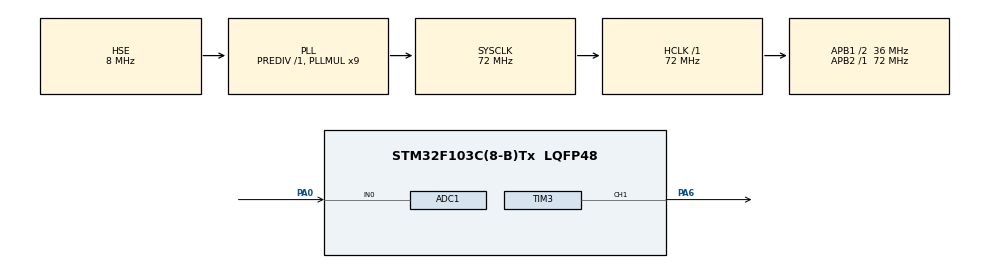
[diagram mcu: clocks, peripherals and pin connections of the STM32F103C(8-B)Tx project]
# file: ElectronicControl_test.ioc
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ADC1.Channel-0\#ChannelRegularConversion=ADC_CHANNEL_0
ADC1.ContinuousConvMode=ENABLE
ADC1.NbrOfConversionFlag=1
ADC1.Rank-0\#ChannelRegularConversion=1
ADC1.SamplingTime-0\#ChannelRegularConversion=ADC_SAMPLETIME_55CYCLES_5
ADC1.master=1
Dma.ADC1.0.Direction=DMA_PERIPH_TO_MEMORY
Dma.ADC1.0.Instance=DMA1_Channel1
Dma.ADC1.0.MemDataAlignment=DMA_MDATAALIGN_HALFWORD
Dma.ADC1.0.MemInc=DMA_MINC_ENABLE
Dma.ADC1.0.Mode=DMA_CIRCULAR
Dma.ADC1.0.PeriphDataAlignment=DMA_PDATAALIGN_HALFWORD
Dma.ADC1.0.PeriphInc=DMA_PINC_DISABLE
Dma.ADC1.0.Priority=DMA_PRIORITY_HIGH
Dma.Request0=ADC1
Mcu.Family=STM32F1
Mcu.Name=STM32F103C(8-B)Tx
Mcu.Package=LQFP48
NVIC.DMA1_Channel1_IRQn=true\:0\:0\:false\:false\:true\:false\:true\:true
NVIC.PriorityGroup=NVIC_PRIORITYGROUP_4
PA0-WKUP.Signal=ADCx_IN0
PA13.Mode=Serial_Wire
PA13.Signal=SYS_JTMS-SWDIO
PA14.Mode=Serial_Wire
PA14.Signal=SYS_JTCK-SWCLK
PA6.GPIO_Speed=GPIO_SPEED_FREQ_HIGH
PA6.Signal=S_TIM3_CH1
PD0-OSC_IN.Mode=HSE-External-Oscillator
PD0-OSC_IN.Signal=RCC_OSC_IN
PD1-OSC_OUT.Mode=HSE-External-Oscillator
PD1-OSC_OUT.Signal=RCC_OSC_OUT
ProjectManager.HeapSize=0x200
ProjectManager.StackSize=0x400
ProjectManager.TargetToolchain=CMake
RCC.ADCPresc=RCC_ADCPCLK2_DIV6
RCC.AHBFreq_Value=72000000
RCC.APB1CLKDivider=RCC_HCLK_DIV2
RCC.APB1Freq_Value=36000000
RCC.APB1TimFreq_Value=72000000
RCC.APB2Freq_Value=72000000
RCC.APB2TimFreq_Value=72000000
RCC.HCLKFreq_Value=72000000
RCC.PLLMUL=RCC_PLL_MUL9
RCC.PLLSourceVirtual=RCC_PLLSOURCE_HSE
RCC.SYSCLKFreq_VALUE=72000000
RCC.SYSCLKSource=RCC_SYSCLKSOURCE_PLLCLK
RCC.USBFreq_Value=72000000
SH.ADCx_IN0.0=ADC1_IN0,IN0
SH.S_TIM3_CH1.0=TIM3_CH1,PWM Generation1 CH1
TIM3.Channel-PWM\ Generation1\ CH1=TIM_CHANNEL_1
TIM3.Period=999
TIM3.Prescaler=71
board=custom

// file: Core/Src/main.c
/* USER CODE BEGIN Header */
/**
 ******************************************************************************
 * @file           : main.c
 * @brief          : Main program body
 ******************************************************************************
 * @attention
 *
 * Copyright (c) 2026 STMicroelectronics.
 * All rights reserved.
 *
 * This software is licensed under terms that can be found in the LICENSE file
 * in the root directory of this software component.
 * If no LICENSE file comes with this software, it is provided AS-IS.
 *
 ******************************************************************************
 */
/* USER CODE END Header */
#include "main.h"
#include "adc.h"
#include "dma.h"
#include "tim.h"
#include "gpio.h"

#include <stdint.h>

/* USER CODE BEGIN PV */
#define ADC_FULL_SCALE 4096U /* 12 位 ADC 满量程 */
#define MOVING_AVG_LEN 8U    /* 移动平均窗口长度 */

static uint16_t s_adc_raw = 0U;                     /* DMA 目标缓冲区 */
static uint16_t s_adc_filter[MOVING_AVG_LEN] = {0}; /* 滤波环形缓冲 */
static uint8_t s_adc_index = 0U;
static uint32_t s_adc_sum = 0U;
static uint32_t s_pwm_period = 0U; /* = ARR + 1，运行期读取 */
/* USER CODE END PV */

void SystemClock_Config(void);

int main(void) {

    /* MCU Configuration--------------------------------------------------------*/

    /* Reset of all peripherals, Initializes the Flash interface and the Systick. */
    HAL_Init();

    /* Configure the system clock */
    SystemClock_Config();

    /* Initialize all configured peripherals */
    MX_GPIO_Init();
    MX_DMA_Init();
    MX_ADC1_Init();
    MX_TIM3_Init();
    /* USER CODE BEGIN 2 */

    __HAL_TIM_SET_COMPARE(&htim3, TIM_CHANNEL_1, 0U); /* 上电先灭，避免满亮 */
    if (HAL_TIM_PWM_Start(&htim3, TIM_CHANNEL_1) != HAL_OK) {
        Error_Handler();
    }

    s_pwm_period = htim3.Init.Period + 1U; /* ARR=999 → 1000 */

    if (HAL_ADC_Start_DMA(&hadc1, (uint32_t *)&s_adc_raw, 1U) != HAL_OK) {
        Error_Handler();
    }

    /* USER CODE END 2 */

    /* Infinite loop */
    while (1) {

        /* USER CODE BEGIN 3 */
        uint32_t adc_value = s_adc_raw; /* 1. 取最新采样 0~4095 */

        /* 2. 移动平均滤波，消除电位器抖动引起的亮度跳变 */
        s_adc_sum -= s_adc_filter[s_adc_index];
        s_adc_filter[s_adc_index] = (uint16_t)adc_value;
        s_adc_sum += adc_value;
        s_adc_index++;
        if (s_adc_index >= MOVING_AVG_LEN) {
            s_adc_index = 0U;
        }
        uint32_t adc_avg = s_adc_sum / MOVING_AVG_LEN;

        /* 3. 线性映射：ADC 0~4095 → 占空比 0~1000（占空比 0~100%） */
        uint32_t ccr = (uint32_t)(((uint64_t)adc_avg * (uint64_t)s_pwm_period) / ADC_FULL_SCALE);

        /* 4. 更新比较寄存器，亮度随旋钮位置线性变化 */
        __HAL_TIM_SET_COMPARE(&htim3, TIM_CHANNEL_1, ccr);
    }
    /* USER CODE END 3 */
}

void SystemClock_Config(void) {
    RCC_OscInitTypeDef RCC_OscInitStruct = {0};
    RCC_ClkInitTypeDef RCC_ClkInitStruct = {0};
    RCC_PeriphCLKInitTypeDef PeriphClkInit = {0};

    /** Initializes the RCC Oscillators according to the specified parameters
     * in the RCC_OscInitTypeDef structure.
     */
    RCC_OscInitStruct.OscillatorType = RCC_OSCILLATORTYPE_HSE;
    RCC_OscInitStruct.HSEState = RCC_HSE_ON;
    RCC_OscInitStruct.HSEPredivValue = RCC_HSE_PREDIV_DIV1;
    RCC_OscInitStruct.HSIState = RCC_HSI_ON;
    RCC_OscInitStruct.PLL.PLLState = RCC_PLL_ON;
    RCC_OscInitStruct.PLL.PLLSource = RCC_PLLSOURCE_HSE;
    RCC_OscInitStruct.PLL.PLLMUL = RCC_PLL_MUL9;
    if (HAL_RCC_OscConfig(&RCC_OscInitStruct) != HAL_OK) {
        Error_Handler();
    }

    /** Initializes the CPU, AHB and APB buses clocks
     */
    RCC_ClkInitStruct.ClockType = RCC_CLOCKTYPE_HCLK | RCC_CLOCKTYPE_SYSCLK
                                  | RCC_CLOCKTYPE_PCLK1 | RCC_CLOCKTYPE_PCLK2;
    RCC_ClkInitStruct.SYSCLKSource = RCC_SYSCLKSOURCE_PLLCLK;
    RCC_ClkInitStruct.AHBCLKDivider = RCC_SYSCLK_DIV1;
    RCC_ClkInitStruct.APB1CLKDivider = RCC_HCLK_DIV2;
    RCC_ClkInitStruct.APB2CLKDivider = RCC_HCLK_DIV1;

    if (HAL_RCC_ClockConfig(&RCC_ClkInitStruct, FLASH_LATENCY_2) != HAL_OK) {
        Error_Handler();
    }
    PeriphClkInit.PeriphClockSelection = RCC_PERIPHCLK_ADC;
    PeriphClkInit.AdcClockSelection = RCC_ADCPCLK2_DIV6;
    if (HAL_RCCEx_PeriphCLKConfig(&PeriphClkInit) != HAL_OK) {
        Error_Handler();
    }
}

void Error_Handler(void) {
    __disable_irq();
    while (1) {
    }
}
